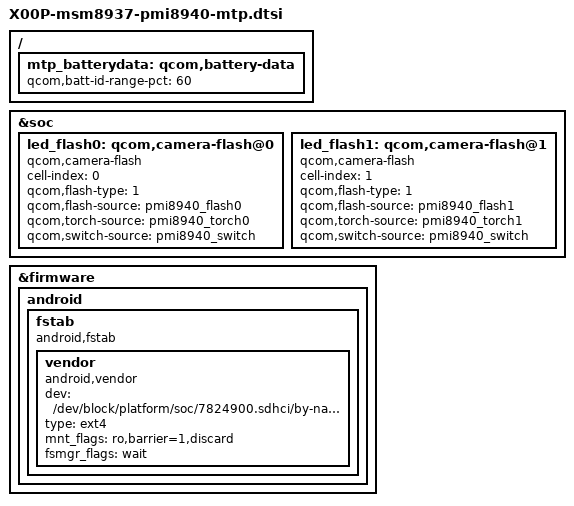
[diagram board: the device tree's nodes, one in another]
/*
 * Copyright (c) 2017, The Linux Foundation. All rights reserved.
 *
 * This program is free software; you can redistribute it and/or modify
 * it under the terms of the GNU General Public License version 2 and
 * only version 2 as published by the Free Software Foundation.
 *
 * This program is distributed in the hope that it will be useful,
 * but WITHOUT ANY WARRANTY; without even the implied warranty of
 * MERCHANTABILITY or FITNESS FOR A PARTICULAR PURPOSE.  See the
 * GNU General Public License for more details.
 */

&soc {
	/delete-node/ qcom,camera-flash;

	led_flash0: qcom,camera-flash@0 {
		cell-index = <0>;
		compatible = "qcom,camera-flash";
		qcom,flash-type = <1>;
		qcom,flash-source = <&pmi8940_flash0>;
		qcom,torch-source = <&pmi8940_torch0>;
		qcom,switch-source = <&pmi8940_switch>;
		status = "ok";
	};
	
	led_flash1: qcom,camera-flash@1 {
		cell-index = <1>;
		compatible = "qcom,camera-flash";
		qcom,flash-type = <1>;
		qcom,flash-source = <&pmi8940_flash1>;
		qcom,torch-source = <&pmi8940_torch1>;
		qcom,switch-source = <&pmi8940_switch>;
		status = "ok";
	};
};

/{
	/delete-node/ qcom,battery-data;

	mtp_batterydata: qcom,battery-data {
		qcom,batt-id-range-pct = <60>;

		#include "battery/batterydata-ascent-3700mAh.dtsi"
		#include "battery/3340624_Wind_E300cos_4000mAh_averaged_MasterSlave_Feb20th2018_PMI8940.dtsi"
	};
};

&firmware {
	android {
		/delete-node/ vbmeta;
		
		fstab {
			compatible = "android,fstab";

			vendor {
				compatible = "android,vendor";
				dev = "/dev/block/platform/soc/7824900.sdhci/by-name/vendor";
				type = "ext4";
				mnt_flags = "ro,barrier=1,discard";
				fsmgr_flags = "wait";
				status = "ok";
			};
		};
	};
};
